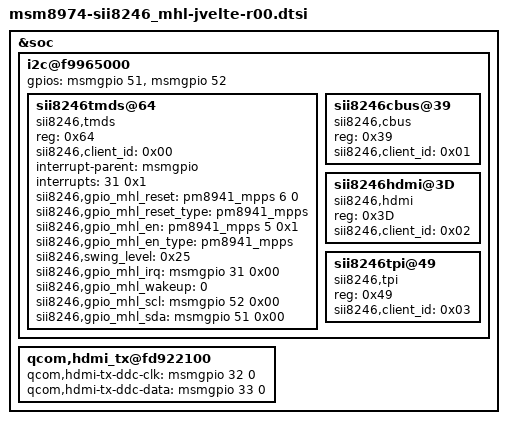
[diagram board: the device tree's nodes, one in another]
/* Copyright (c) 2012, Samsung Electronics Corporation. All rights reserved.
 *
 * This program is free software; you can redistribute it and/or modify
 * it under the terms of the GNU General Public License version 2 and
 * only version 2 as published by the Free Software Foundation.
 *
 * This program is distributed in the hope that it will be useful,
 * but WITHOUT ANY WARRANTY; without even the implied warranty of
 * MERCHANTABILITY or FITNESS FOR A PARTICULAR PURPOSE.  See the
 * GNU General Public License for more details.
 */

&soc {
	i2c@f9965000 {
		gpios = <&msmgpio 51 0>, /* sda */
			<&msmgpio 52 0>; /* scl */

		sii8246tmds@64 {
			compatible = "sii8246,tmds";
			reg = <0x64>;  /* 0xC8 >> 1 */
			sii8246,client_id = <0x00>;

			interrupt-parent = <&msmgpio>;
			interrupts = <31 0x1>;
			sii8246,gpio_mhl_reset = <&pm8941_mpps 6 0>;  /*&msmgpio 60 0x00*/
                        sii8246,gpio_mhl_reset_type = "pm8941_mpps";
			sii8246,gpio_mhl_en = <&pm8941_mpps 5 0x1>;
                        sii8246,gpio_mhl_en_type = "pm8941_mpps";
			sii8246,swing_level = <0x25>;

			sii8246,gpio_mhl_irq = <&msmgpio 31 0x00>;
			sii8246,gpio_mhl_wakeup = <0>; /* <&msmgpio 96 0x00>; */
			sii8246,gpio_mhl_scl = <&msmgpio 52 0x00>;
			sii8246,gpio_mhl_sda = <&msmgpio 51 0x00>;
/*			sii8246,barcode_emul;*/
/*			vcc_1p2v-supply  = <&pm8941_l11>;*/ /*<&pm8941_l11> */
/*			vcc_1p8v-supply  = <&pm8941_l10>;*/ /*<&pm8941_l10> */
/*			vcc_3p3v-supply  = <&pm8941_l19>;*/ /*<&pm8941_l19> */
		};
		sii8246cbus@39 {
			compatible = "sii8246,cbus";
			reg = <0x39>; /* 0x72 >> 1 */
			sii8246,client_id = <0x01>;
		};
		sii8246hdmi@3D {
			compatible = "sii8246,hdmi";
			reg = <0x3D>;  /* 0x7A >> 1 */
			sii8246,client_id = <0x02>;
		};
		sii8246tpi@49 {
			compatible = "sii8246,tpi";
			reg = <0x49>; /* 0x92 >> 1 */
			sii8246,client_id = <0x03>;
		};
	};
	qcom,hdmi_tx@fd922100 {
		      qcom,hdmi-tx-ddc-clk = <&msmgpio 32 0>;
		      qcom,hdmi-tx-ddc-data = <&msmgpio 33 0>;
		};
};
